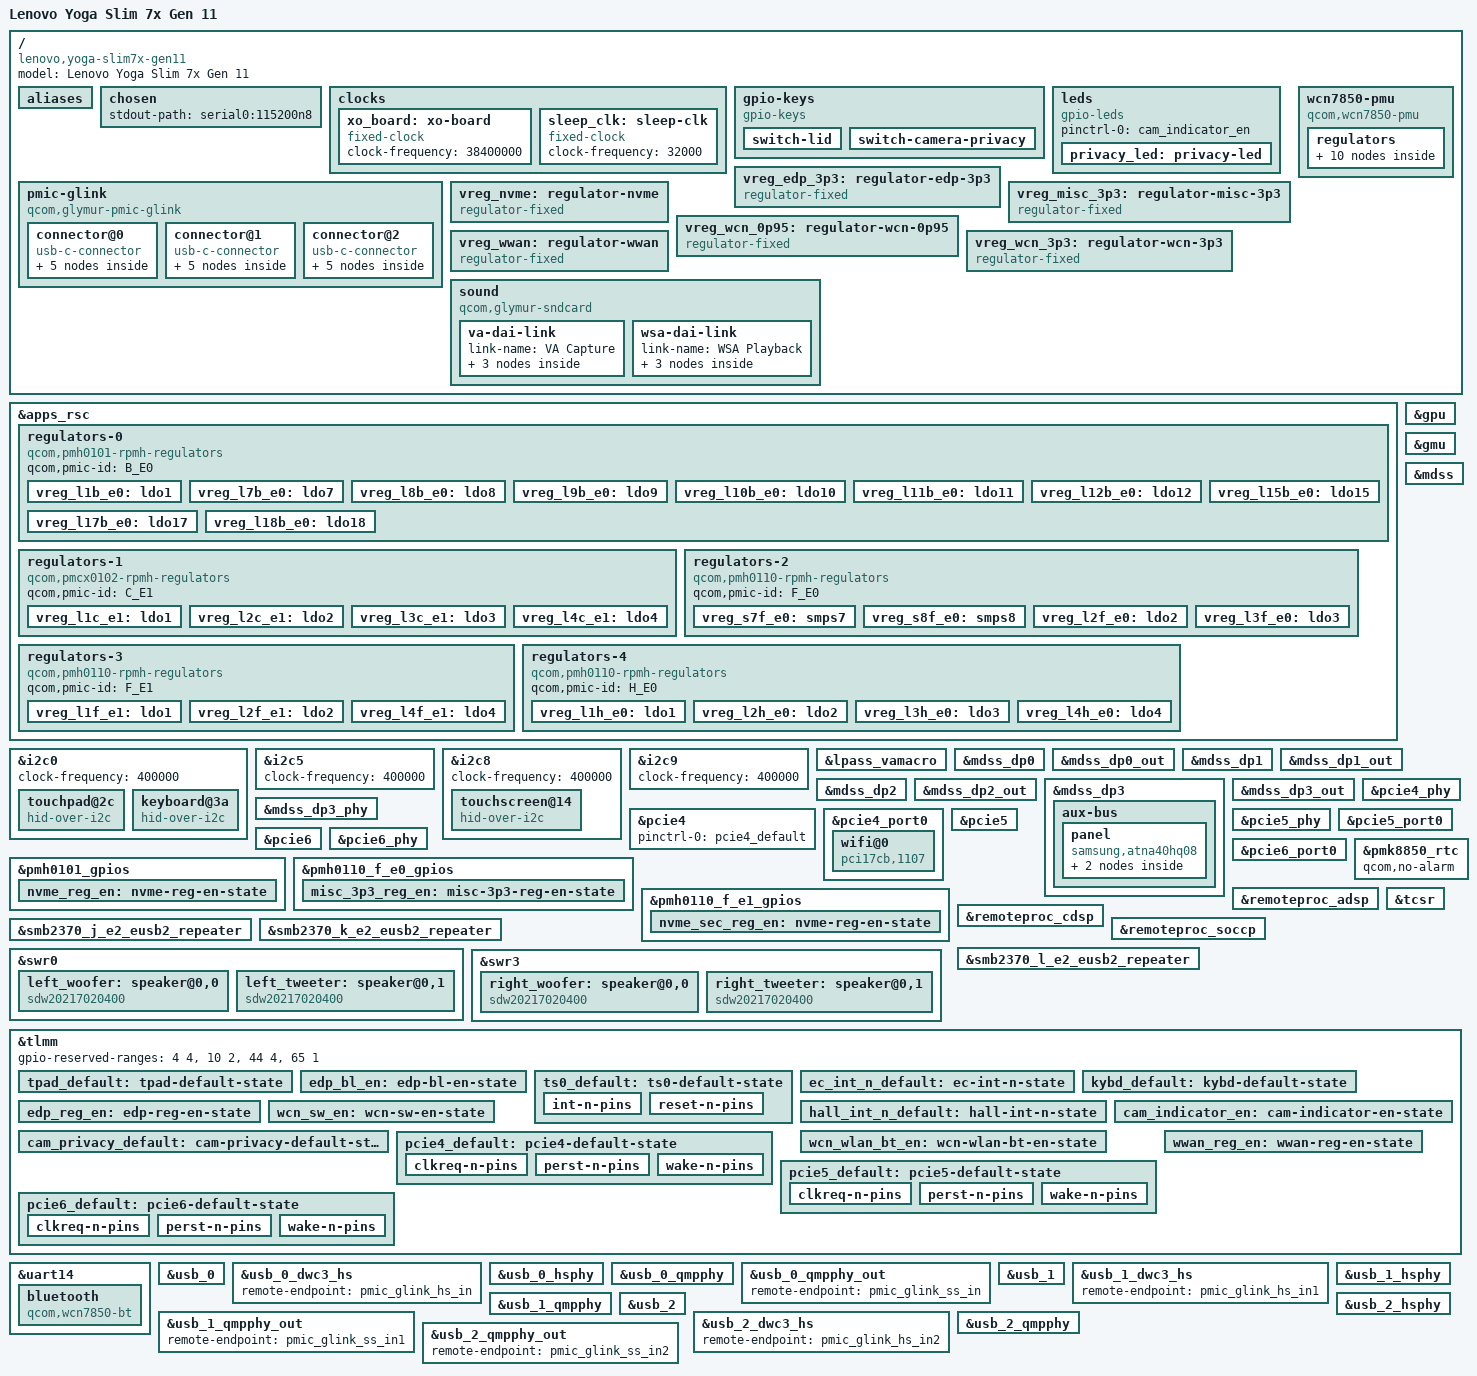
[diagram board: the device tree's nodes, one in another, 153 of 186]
// SPDX-License-Identifier: BSD-3-Clause
/*
 * Copyright (c) Qualcomm Technologies, Inc. and/or its subsidiaries.
 */
/dts-v1/;

#include "glymur.dtsi"

#include "pmcx0102.dtsi"        /* SPMI0: SID-2/3 SPMI1: SID-2/3 */
#include "pmh0101.dtsi"         /* SPMI0: SID-1                  */
#include "pmh0110-glymur.dtsi"  /* SPMI0: SID-5/7 SPMI1: SID-5   */
#include "pmh0104-glymur.dtsi"  /* SPMI0: SID-8/9 SPMI1: SID-11  */
#include "pmk8850.dtsi"         /* SPMI0: SID-0                  */
#include "smb2370.dtsi"         /* SPMI2: SID-9/10/11            */

#include <dt-bindings/input/gpio-keys.h>
#include <dt-bindings/leds/common.h>
#include <dt-bindings/pinctrl/qcom,pmic-gpio.h>

/ {
	model = "Lenovo Yoga Slim 7x Gen 11";
	compatible = "lenovo,yoga-slim7x-gen11", "qcom,glymur";

	aliases {
		serial0 = &uart21;
		serial1 = &uart14;
		i2c0 = &i2c0;
		i2c5 = &i2c5;
		i2c8 = &i2c8;
		i2c9 = &i2c9;
	};

	chosen {
		stdout-path = "serial0:115200n8";
	};

	clocks {
		xo_board: xo-board {
			compatible = "fixed-clock";
			clock-frequency = <38400000>;
			#clock-cells = <0>;
		};

		sleep_clk: sleep-clk {
			compatible = "fixed-clock";
			clock-frequency = <32000>;
			#clock-cells = <0>;
		};
	};

	gpio-keys {
		compatible = "gpio-keys";

		pinctrl-0 = <&hall_int_n_default>, <&cam_privacy_default>;
		pinctrl-names = "default";

		switch-lid {
			label = "lid";
			gpios = <&tlmm 92 GPIO_ACTIVE_LOW>;
			linux,input-type = <EV_SW>;
			linux,code = <SW_LID>;
			wakeup-source;
			wakeup-event-action = <EV_ACT_DEASSERTED>;
		};

		switch-camera-privacy {
			label = "Camera privacy switch";
			gpios = <&tlmm 99 GPIO_ACTIVE_LOW>;
			linux,input-type = <EV_SW>;
			linux,code = <SW_CAMERA_LENS_COVER>;
		};
	};

	leds {
		compatible = "gpio-leds";

		pinctrl-0 = <&cam_indicator_en>;
		pinctrl-names = "default";

		privacy_led: privacy-led {
			function = LED_FUNCTION_INDICATOR;
			color = <LED_COLOR_ID_WHITE>;
			gpios = <&tlmm 111 GPIO_ACTIVE_HIGH>;
			default-state = "off";
			panic-indicator;
		};
	};

	pmic-glink {
		compatible = "qcom,glymur-pmic-glink",
			     "qcom,pmic-glink";
		#address-cells = <1>;
		#size-cells = <0>;

		/* Left side display-adjacent port */
		connector@0 {
			compatible = "usb-c-connector";
			reg = <0>;
			power-role = "dual";
			data-role = "dual";

			ports {
				#address-cells = <1>;
				#size-cells = <0>;

				port@0 {
					reg = <0>;

					pmic_glink_hs_in: endpoint {
						remote-endpoint = <&usb_0_dwc3_hs>;
					};
				};

				port@1 {
					reg = <1>;

					pmic_glink_ss_in: endpoint {
						remote-endpoint = <&usb_0_qmpphy_out>;
					};
				};
			};
		};

		/* Left side user-adjacent port */
		connector@1 {
			compatible = "usb-c-connector";
			reg = <1>;
			power-role = "dual";
			data-role = "dual";

			ports {
				#address-cells = <1>;
				#size-cells = <0>;

				port@0 {
					reg = <0>;

					pmic_glink_hs_in1: endpoint {
						remote-endpoint = <&usb_1_dwc3_hs>;
					};
				};

				port@1 {
					reg = <1>;

					pmic_glink_ss_in1: endpoint {
						remote-endpoint = <&usb_1_qmpphy_out>;
					};
				};
			};
		};

		/* Right side port */
		connector@2 {
			compatible = "usb-c-connector";
			reg = <2>;
			power-role = "dual";
			data-role = "dual";

			ports {
				#address-cells = <1>;
				#size-cells = <0>;

				port@0 {
					reg = <0>;

					pmic_glink_hs_in2: endpoint {
						remote-endpoint = <&usb_2_dwc3_hs>;
					};
				};

				port@1 {
					reg = <1>;

					pmic_glink_ss_in2: endpoint {
						remote-endpoint = <&usb_2_qmpphy_out>;
					};
				};
			};
		};
	};

	vreg_edp_3p3: regulator-edp-3p3 {
		compatible = "regulator-fixed";

		regulator-name = "VREG_EDP_3P3";
		regulator-min-microvolt = <3300000>;
		regulator-max-microvolt = <3300000>;

		gpio = <&tlmm 70 GPIO_ACTIVE_HIGH>;
		enable-active-high;

		pinctrl-0 = <&edp_reg_en>;
		pinctrl-names = "default";

		regulator-boot-on;
	};

	vreg_misc_3p3: regulator-misc-3p3 {
		compatible = "regulator-fixed";

		regulator-name = "VREG_MISC_3P3";
		regulator-min-microvolt = <3300000>;
		regulator-max-microvolt = <3300000>;

		gpio = <&pmh0110_f_e0_gpios 6 GPIO_ACTIVE_HIGH>;
		enable-active-high;

		pinctrl-0 = <&misc_3p3_reg_en>;
		pinctrl-names = "default";

		regulator-boot-on;
	};

	vreg_nvme: regulator-nvme {
		compatible = "regulator-fixed";

		regulator-name = "VREG_NVME_3P3";
		regulator-min-microvolt = <3300000>;
		regulator-max-microvolt = <3300000>;

		gpio = <&pmh0101_gpios 14 GPIO_ACTIVE_HIGH>;
		enable-active-high;

		pinctrl-0 = <&nvme_reg_en>;
		pinctrl-names = "default";

		regulator-boot-on;
	};

	vreg_wcn_0p95: regulator-wcn-0p95 {
		compatible = "regulator-fixed";

		regulator-name = "VREG_WCN_0P95";
		regulator-min-microvolt = <950000>;
		regulator-max-microvolt = <950000>;

		vin-supply = <&vreg_wcn_3p3>;
	};

	vreg_wcn_3p3: regulator-wcn-3p3 {
		compatible = "regulator-fixed";

		regulator-name = "VREG_WCN_3P3";
		regulator-min-microvolt = <3300000>;
		regulator-max-microvolt = <3300000>;

		gpio = <&tlmm 94 GPIO_ACTIVE_HIGH>;
		enable-active-high;

		pinctrl-0 = <&wcn_sw_en>;
		pinctrl-names = "default";

		regulator-boot-on;
	};

	vreg_wwan: regulator-wwan {
		compatible = "regulator-fixed";

		regulator-name = "VREG_WWAN_3P3";
		regulator-min-microvolt = <3300000>;
		regulator-max-microvolt = <3300000>;

		gpio = <&tlmm 246 GPIO_ACTIVE_HIGH>;
		enable-active-high;

		pinctrl-0 = <&wwan_reg_en>;
		pinctrl-names = "default";
	};

	sound {
		compatible = "qcom,glymur-sndcard";
		model = "GLYMUR-LENOVO-Yoga-Slim7x";
		audio-routing = "WooferLeft IN", "WSA WSA_SPK1 OUT",
				"TweeterLeft IN", "WSA WSA_SPK2 OUT",
				"WooferRight IN", "WSA2 WSA_SPK1 OUT",
				"TweeterRight IN", "WSA2 WSA_SPK2 OUT",
				"VA DMIC0", "vdd-micb",
				"VA DMIC1", "vdd-micb",
				"VA DMIC2", "vdd-micb",
				"VA DMIC3", "vdd-micb";

		va-dai-link {
			link-name = "VA Capture";

			codec {
				sound-dai = <&lpass_vamacro 0>;
			};

			cpu {
				sound-dai = <&q6apmbedai VA_CODEC_DMA_TX_0>;
			};

			platform {
				sound-dai = <&q6apm>;
			};
		};

		wsa-dai-link {
			link-name = "WSA Playback";

			codec {
				sound-dai = <&left_woofer>, <&left_tweeter>,
					    <&swr0 0>, <&lpass_wsamacro 0>,
					    <&right_woofer>, <&right_tweeter>,
					    <&swr3 0>, <&lpass_wsa2macro 0>;
			};

			cpu {
				sound-dai = <&q6apmbedai WSA_CODEC_DMA_RX_0>;
			};

			platform {
				sound-dai = <&q6apm>;
			};
		};
	};

	wcn7850-pmu {
		compatible = "qcom,wcn7850-pmu";

		vdd-supply = <&vreg_wcn_0p95>;
		vddio-supply = <&vreg_l15b_e0>;
		vddaon-supply = <&vreg_l15b_e0>;
		vdddig-supply = <&vreg_l15b_e0>;
		vddrfa1p2-supply = <&vreg_l15b_e0>;
		vddrfa1p8-supply = <&vreg_l15b_e0>;

		wlan-enable-gpios = <&tlmm 117 GPIO_ACTIVE_HIGH>;
		bt-enable-gpios = <&tlmm 116 GPIO_ACTIVE_HIGH>;

		pinctrl-0 = <&wcn_wlan_bt_en>;
		pinctrl-names = "default";

		regulators {
			vreg_pmu_rfa_cmn: ldo0 {
				regulator-name = "vreg_pmu_rfa_cmn";
			};

			vreg_pmu_aon_0p59: ldo1 {
				regulator-name = "vreg_pmu_aon_0p59";
			};

			vreg_pmu_wlcx_0p8: ldo2 {
				regulator-name = "vreg_pmu_wlcx_0p8";
			};

			vreg_pmu_wlmx_0p85: ldo3 {
				regulator-name = "vreg_pmu_wlmx_0p85";
			};

			vreg_pmu_btcmx_0p85: ldo4 {
				regulator-name = "vreg_pmu_btcmx_0p85";
			};

			vreg_pmu_rfa_0p8: ldo5 {
				regulator-name = "vreg_pmu_rfa_0p8";
			};

			vreg_pmu_rfa_1p2: ldo6 {
				regulator-name = "vreg_pmu_rfa_1p2";
			};

			vreg_pmu_rfa_1p8: ldo7 {
				regulator-name = "vreg_pmu_rfa_1p8";
			};

			vreg_pmu_pcie_0p9: ldo8 {
				regulator-name = "vreg_pmu_pcie_0p9";
			};

			vreg_pmu_pcie_1p8: ldo9 {
				regulator-name = "vreg_pmu_pcie_1p8";
			};
		};
	};
};

&apps_rsc {
	regulators-0 {
		compatible = "qcom,pmh0101-rpmh-regulators";
		qcom,pmic-id = "B_E0";

		vreg_l1b_e0: ldo1 {
			regulator-name = "vreg_l1b_e0";
			regulator-min-microvolt = <1800000>;
			regulator-max-microvolt = <1800000>;
			regulator-initial-mode = <RPMH_REGULATOR_MODE_HPM>;
		};

		vreg_l7b_e0: ldo7 {
			regulator-name = "vreg_l7b_e0";
			regulator-min-microvolt = <3072000>;
			regulator-max-microvolt = <3072000>;
			regulator-initial-mode = <RPMH_REGULATOR_MODE_HPM>;
		};

		vreg_l8b_e0: ldo8 {
			regulator-name = "vreg_l8b_e0";
			regulator-min-microvolt = <3304000>;
			regulator-max-microvolt = <3304000>;
			regulator-initial-mode = <RPMH_REGULATOR_MODE_HPM>;
		};

		vreg_l9b_e0: ldo9 {
			regulator-name = "vreg_l9b_e0";
			regulator-min-microvolt = <2960000>;
			regulator-max-microvolt = <2960000>;
			regulator-initial-mode = <RPMH_REGULATOR_MODE_HPM>;
		};

		vreg_l10b_e0: ldo10 {
			regulator-name = "vreg_l10b_e0";
			regulator-min-microvolt = <1800000>;
			regulator-max-microvolt = <1800000>;
			regulator-initial-mode = <RPMH_REGULATOR_MODE_HPM>;
		};

		vreg_l11b_e0: ldo11 {
			regulator-name = "vreg_l11b_e0";
			regulator-min-microvolt = <1200000>;
			regulator-max-microvolt = <1200000>;
			regulator-initial-mode = <RPMH_REGULATOR_MODE_HPM>;
		};

		vreg_l12b_e0: ldo12 {
			regulator-name = "vreg_l12b_e0";
			regulator-min-microvolt = <1200000>;
			regulator-max-microvolt = <1200000>;
			regulator-initial-mode = <RPMH_REGULATOR_MODE_HPM>;
		};

		vreg_l15b_e0: ldo15 {
			regulator-name = "vreg_l15b_e0";
			regulator-min-microvolt = <1800000>;
			regulator-max-microvolt = <1800000>;
			regulator-initial-mode = <RPMH_REGULATOR_MODE_HPM>;
		};

		vreg_l17b_e0: ldo17 {
			regulator-name = "vreg_l17b_e0";
			regulator-min-microvolt = <2504000>;
			regulator-max-microvolt = <2504000>;
			regulator-initial-mode = <RPMH_REGULATOR_MODE_HPM>;
		};

		vreg_l18b_e0: ldo18 {
			regulator-name = "vreg_l18b_e0";
			regulator-min-microvolt = <1200000>;
			regulator-max-microvolt = <1200000>;
			regulator-initial-mode = <RPMH_REGULATOR_MODE_HPM>;
		};
	};

	regulators-1 {
		compatible = "qcom,pmcx0102-rpmh-regulators";
		qcom,pmic-id = "C_E1";

		vreg_l1c_e1: ldo1 {
			regulator-name = "vreg_l1c_e1";
			regulator-min-microvolt = <912000>;
			regulator-max-microvolt = <912000>;
			regulator-initial-mode = <RPMH_REGULATOR_MODE_HPM>;
		};

		vreg_l2c_e1: ldo2 {
			regulator-name = "vreg_l2c_e1";
			regulator-min-microvolt = <1200000>;
			regulator-max-microvolt = <1200000>;
			regulator-initial-mode = <RPMH_REGULATOR_MODE_HPM>;
		};

		vreg_l3c_e1: ldo3 {
			regulator-name = "vreg_l3c_e1";
			regulator-min-microvolt = <936000>;
			regulator-max-microvolt = <936000>;
			regulator-initial-mode = <RPMH_REGULATOR_MODE_HPM>;
		};

		vreg_l4c_e1: ldo4 {
			regulator-name = "vreg_l4c_e1";
			regulator-min-microvolt = <912000>;
			regulator-max-microvolt = <912000>;
			regulator-initial-mode = <RPMH_REGULATOR_MODE_HPM>;
		};
	};

	regulators-2 {
		compatible = "qcom,pmh0110-rpmh-regulators";
		qcom,pmic-id = "F_E0";

		vreg_s7f_e0: smps7 {
			regulator-name = "vreg_s7f_e0";
			regulator-min-microvolt = <1200000>;
			regulator-max-microvolt = <1200000>;
			regulator-initial-mode = <RPMH_REGULATOR_MODE_HPM>;
		};

		vreg_s8f_e0: smps8 {
			regulator-name = "vreg_s8f_e0";
			regulator-min-microvolt = <952000>;
			regulator-max-microvolt = <952000>;
			regulator-initial-mode = <RPMH_REGULATOR_MODE_HPM>;
		};

		vreg_l2f_e0: ldo2 {
			regulator-name = "vreg_l2f_e0";
			regulator-min-microvolt = <936000>;
			regulator-max-microvolt = <936000>;
			regulator-initial-mode = <RPMH_REGULATOR_MODE_HPM>;
		};

		vreg_l3f_e0: ldo3 {
			regulator-name = "vreg_l3f_e0";
			regulator-min-microvolt = <912000>;
			regulator-max-microvolt = <912000>;
			regulator-initial-mode = <RPMH_REGULATOR_MODE_HPM>;
		};
	};

	regulators-3 {
		compatible = "qcom,pmh0110-rpmh-regulators";
		qcom,pmic-id = "F_E1";

		vreg_l1f_e1: ldo1 {
			regulator-name = "vreg_l1f_e1";
			regulator-min-microvolt = <880000>;
			regulator-max-microvolt = <904000>;
			regulator-initial-mode = <RPMH_REGULATOR_MODE_HPM>;
		};

		vreg_l2f_e1: ldo2 {
			regulator-name = "vreg_l2f_e1";
			regulator-min-microvolt = <880000>;
			regulator-max-microvolt = <880000>;
			regulator-initial-mode = <RPMH_REGULATOR_MODE_HPM>;
		};

		vreg_l4f_e1: ldo4 {
			regulator-name = "vreg_l4f_e1";
			regulator-min-microvolt = <1200000>;
			regulator-max-microvolt = <1200000>;
			regulator-initial-mode = <RPMH_REGULATOR_MODE_HPM>;
		};
	};

	regulators-4 {
		compatible = "qcom,pmh0110-rpmh-regulators";
		qcom,pmic-id = "H_E0";

		vreg_l1h_e0: ldo1 {
			regulator-name = "vreg_l1h_e0";
			regulator-min-microvolt = <936000>;
			regulator-max-microvolt = <936000>;
			regulator-initial-mode = <RPMH_REGULATOR_MODE_HPM>;
		};

		vreg_l2h_e0: ldo2 {
			regulator-name = "vreg_l2h_e0";
			regulator-min-microvolt = <880000>;
			regulator-max-microvolt = <880000>;
			regulator-initial-mode = <RPMH_REGULATOR_MODE_HPM>;
		};

		vreg_l3h_e0: ldo3 {
			regulator-name = "vreg_l3h_e0";
			regulator-min-microvolt = <1800000>;
			regulator-max-microvolt = <1800000>;
			regulator-initial-mode = <RPMH_REGULATOR_MODE_HPM>;
		};

		vreg_l4h_e0: ldo4 {
			regulator-name = "vreg_l4h_e0";
			regulator-min-microvolt = <1200000>;
			regulator-max-microvolt = <1200000>;
			regulator-initial-mode = <RPMH_REGULATOR_MODE_HPM>;
		};
	};
};

&gpu {
	status = "okay";
};

&gmu {
	status = "okay";
};

&i2c0 {
	clock-frequency = <400000>;

	status = "okay";

	touchpad@2c {
		compatible = "hid-over-i2c";
		reg = <0x2c>;

		hid-descr-addr = <0x20>;
		interrupts-extended = <&tlmm 3 IRQ_TYPE_LEVEL_LOW>;

		vdd-supply = <&vreg_misc_3p3>;
		vddl-supply = <&vreg_l15b_e0>;

		pinctrl-0 = <&tpad_default>;
		pinctrl-names = "default";

		wakeup-source;
	};

	keyboard@3a {
		compatible = "hid-over-i2c";
		reg = <0x3a>;

		hid-descr-addr = <0x1>;
		interrupts-extended = <&tlmm 67 IRQ_TYPE_LEVEL_LOW>;

		vdd-supply = <&vreg_misc_3p3>;
		vddl-supply = <&vreg_l15b_e0>;

		pinctrl-0 = <&kybd_default>;
		pinctrl-names = "default";

		wakeup-source;
	};

	/* Something @ 0x5b */
};

&i2c5 {
	clock-frequency = <400000>;

	status = "okay";
};

&i2c8 {
	clock-frequency = <400000>;

	status = "okay";

	touchscreen@14 {
		compatible = "hid-over-i2c";
		reg = <0x14>;

		hid-descr-addr = <0x1>;
		interrupts-extended = <&tlmm 51 IRQ_TYPE_LEVEL_LOW>;

		post-power-on-delay-ms = <200>;

		vdd-supply = <&vreg_misc_3p3>;
		vddl-supply = <&vreg_l15b_e0>;

		pinctrl-0 = <&ts0_default>;
		pinctrl-names = "default";
	};
};

&i2c9 {
	clock-frequency = <400000>;

	status = "okay";

	/* EC @ 0x70, irq = TLMM 66 */
};

&lpass_vamacro {
	pinctrl-0 = <&dmic01_default>, <&dmic23_default>;
	pinctrl-names = "default";
	qcom,dmic-sample-rate = <4800000>;
};

&mdss {
	status = "okay";
};

&mdss_dp0 {
	status = "okay";
};

&mdss_dp0_out {
	link-frequencies = /bits/ 64 <1620000000 2700000000 5400000000 8100000000>;
};

&mdss_dp1 {
	status = "okay";
};

&mdss_dp1_out {
	link-frequencies = /bits/ 64 <1620000000 2700000000 5400000000 8100000000>;
};

&mdss_dp2 {
	status = "okay";
};

&mdss_dp2_out {
	link-frequencies = /bits/ 64 <1620000000 2700000000 5400000000 8100000000>;
};

&mdss_dp3 {
	/delete-property/ #sound-dai-cells;

	status = "okay";

	aux-bus {
		panel {
			compatible = "samsung,atna40hq08", "samsung,atna33xc20";
			enable-gpios = <&tlmm 18 GPIO_ACTIVE_HIGH>;
			power-supply = <&vreg_edp_3p3>;

			pinctrl-0 = <&edp_bl_en>;
			pinctrl-names = "default";

			port {
				edp_panel_in: endpoint {
					remote-endpoint = <&mdss_dp3_out>;
				};
			};
		};
	};
};

&mdss_dp3_out {
	data-lanes = <0 1 2 3>;
	link-frequencies = /bits/ 64 <1620000000 2700000000 5400000000 8100000000>;

	remote-endpoint = <&edp_panel_in>;
};

&mdss_dp3_phy {
	vdda-phy-supply = <&vreg_l2f_e1>;
	vdda-pll-supply = <&vreg_l4f_e1>;

	status = "okay";
};

&pcie4 {
	pinctrl-0 = <&pcie4_default>;
	pinctrl-names = "default";

	status = "okay";
};

&pcie4_phy {
	vdda-phy-supply = <&vreg_l1c_e1>;
	vdda-pll-supply = <&vreg_l4f_e1>;

	status = "okay";
};

&pcie4_port0 {
	reset-gpios = <&tlmm 146 GPIO_ACTIVE_LOW>;
	wake-gpios = <&tlmm 148 GPIO_ACTIVE_LOW>;

	wifi@0 {
		compatible = "pci17cb,1107";
		reg = <0x10000 0x0 0x0 0x0 0x0>;

		vddaon-supply = <&vreg_pmu_aon_0p59>;
		vddwlcx-supply = <&vreg_pmu_wlcx_0p8>;
		vddwlmx-supply = <&vreg_pmu_wlmx_0p85>;
		vddrfacmn-supply = <&vreg_pmu_rfa_cmn>;
		vddrfa0p8-supply = <&vreg_pmu_rfa_0p8>;
		vddrfa1p2-supply = <&vreg_pmu_rfa_1p2>;
		vddrfa1p8-supply = <&vreg_pmu_rfa_1p8>;
		vddpcie0p9-supply = <&vreg_pmu_pcie_0p9>;
		vddpcie1p8-supply = <&vreg_pmu_pcie_1p8>;
	};
};

&pcie5 {
	vddpe-3v3-supply = <&vreg_nvme>;

	pinctrl-0 = <&pcie5_default>;
	pinctrl-names = "default";

	status = "okay";
};

&pcie5_phy {
	vdda-phy-supply = <&vreg_l2f_e0>;
	vdda-pll-supply = <&vreg_l4h_e0>;

	status = "okay";
};

&pcie5_port0 {
	reset-gpios = <&tlmm 152 GPIO_ACTIVE_LOW>;
	wake-gpios = <&tlmm 154 GPIO_ACTIVE_LOW>;
};

&pcie6 {
	vddpe-3v3-supply = <&vreg_wwan>;

	pinctrl-0 = <&pcie6_default>;
	pinctrl-names = "default";

	status = "okay";
};

&pcie6_phy {
	vdda-phy-supply = <&vreg_l1c_e1>;
	vdda-pll-supply = <&vreg_l4f_e1>;

	status = "okay";
};

&pcie6_port0 {
	reset-gpios = <&tlmm 149 GPIO_ACTIVE_LOW>;
	wake-gpios = <&tlmm 151 GPIO_ACTIVE_LOW>;
};

&pmh0101_gpios {
	nvme_reg_en: nvme-reg-en-state {
		pins = "gpio14";
		function = "normal";
		bias-disable;
	};
};

&pmh0110_f_e0_gpios {
	misc_3p3_reg_en: misc-3p3-reg-en-state {
		pins = "gpio6";
		function = "normal";
		bias-disable;
		input-disable;
		output-enable;
		drive-push-pull;
		power-source = <1>; /* 1.8 V */
		qcom,drive-strength = <PMIC_GPIO_STRENGTH_LOW>;
	};
};

&pmh0110_f_e1_gpios {
	nvme_sec_reg_en: nvme-reg-en-state {
		pins = "gpio14";
		function = "normal";
		bias-disable;
	};
};

&pmk8850_rtc {
	qcom,no-alarm;
};

&remoteproc_adsp {
	firmware-name = "qcom/glymur/LENOVO/83QR/qcadsp8480.mbn",
			"qcom/glymur/LENOVO/83QR/adsp_dtbs.elf";

	status = "okay";
};

&remoteproc_cdsp {
	firmware-name = "qcom/glymur/LENOVO/83QR/qccdsp8480.mbn",
			"qcom/glymur/LENOVO/83QR/cdsp_dtbs.elf";

	status = "okay";
};

&remoteproc_soccp {
	status = "okay";
};

&smb2370_j_e2_eusb2_repeater {
	vdd18-supply = <&vreg_l15b_e0>;
	vdd3-supply = <&vreg_l7b_e0>;
};

&smb2370_k_e2_eusb2_repeater {
	vdd18-supply = <&vreg_l15b_e0>;
	vdd3-supply = <&vreg_l7b_e0>;
};

&smb2370_l_e2_eusb2_repeater {
	vdd18-supply = <&vreg_l15b_e0>;
	vdd3-supply = <&vreg_l7b_e0>;

	status = "okay";
};

&swr0 {
	status = "okay";

	/* WSA8845, Left Woofer */
	left_woofer: speaker@0,0 {
		compatible = "sdw20217020400";
		reg = <0 0>;
		reset-gpios = <&lpass_tlmm 12 GPIO_ACTIVE_LOW>;
		#sound-dai-cells = <0>;
		sound-name-prefix = "WooferLeft";
		vdd-1p8-supply = <&vreg_l15b_e0>;
		vdd-io-supply = <&vreg_l18b_e0>;
		qcom,port-mapping = <1 2 3 7 12 14>;
	};

	/* WSA8845, Left Tweeter */
	left_tweeter: speaker@0,1 {
		compatible = "sdw20217020400";
		reg = <0 1>;
		reset-gpios = <&lpass_tlmm 12 GPIO_ACTIVE_LOW>;
		#sound-dai-cells = <0>;
		sound-name-prefix = "TweeterLeft";
		vdd-1p8-supply = <&vreg_l15b_e0>;
		vdd-io-supply = <&vreg_l18b_e0>;
		qcom,port-mapping = <4 5 6 7 13 15>;
	};
};

&swr3 {
	status = "okay";

	/* WSA8845, Right Woofer */
	right_woofer: speaker@0,0 {
		compatible = "sdw20217020400";
		reg = <0 0>;
		reset-gpios = <&lpass_tlmm 13 GPIO_ACTIVE_LOW>;
		#sound-dai-cells = <0>;
		sound-name-prefix = "WooferRight";
		vdd-1p8-supply = <&vreg_l15b_e0>;
		vdd-io-supply = <&vreg_l18b_e0>;
		qcom,port-mapping = <1 2 3 7 12 14>;
	};

	/* WSA8845, Right Tweeter */
	right_tweeter: speaker@0,1 {
		compatible = "sdw20217020400";
		reg = <0 1>;
		reset-gpios = <&lpass_tlmm 13 GPIO_ACTIVE_LOW>;
		#sound-dai-cells = <0>;
		sound-name-prefix = "TweeterRight";
		vdd-1p8-supply = <&vreg_l15b_e0>;
		vdd-io-supply = <&vreg_l18b_e0>;
		qcom,port-mapping = <4 5 6 7 13 15>;
	};
};

&tcsr {
	vdda-qrefrpt0-0p9-supply = <&vreg_l2f_e1>;
	vdda-qrefrpt1-0p9-supply = <&vreg_l2f_e1>;
	vdda-qrefrpt2-0p9-supply = <&vreg_l2f_e1>;
	vdda-qrefrpt3-0p9-supply = <&vreg_l2h_e0>;
	vdda-qrefrpt4-0p9-supply = <&vreg_l2h_e0>;
	vdda-qrefrx0-0p9-supply = <&vreg_l2f_e1>;
	vdda-qrefrx1-0p9-supply = <&vreg_l2f_e1>;
	vdda-qrefrx2-0p9-supply = <&vreg_l2f_e1>;
	vdda-qrefrx4-0p9-supply = <&vreg_l2h_e0>;
	vdda-qrefrx5-0p9-supply = <&vreg_l3f_e0>;
	vdda-qreftx0-0p9-supply = <&vreg_l3f_e0>;
	vdda-qreftx0-1p2-supply = <&vreg_l4h_e0>;
	vdda-qreftx1-0p9-supply = <&vreg_l1f_e1>;
	vdda-refgen3-0p9-supply = <&vreg_l2f_e0>;
	vdda-refgen3-1p2-supply = <&vreg_l4h_e0>;
	vdda-refgen4-0p9-supply = <&vreg_l1f_e1>;
	vdda-refgen4-1p2-supply = <&vreg_l4f_e1>;
};

&tlmm {
	gpio-reserved-ranges = <4 4>, /* EC TZ Secure I3C */
			       <10 2>, /* OOB UART */
			       <44 4>, /* Security SPI (TPM) */
			       <65 1>; /* EC reset (need to unplug the battery if asserted) */

	tpad_default: tpad-default-state {
		pins = "gpio3";
		function = "gpio";
		bias-disable;
	};

	edp_bl_en: edp-bl-en-state {
		pins = "gpio18";
		function = "gpio";
		drive-strength = <16>;
		bias-disable;
	};

	ts0_default: ts0-default-state {
		int-n-pins {
			pins = "gpio51";
			function = "gpio";
			bias-disable;
		};

		reset-n-pins {
			pins = "gpio48";
			function = "gpio";
			drive-strength = <16>;
			bias-disable;
		};
	};

	ec_int_n_default: ec-int-n-state {
		pins = "gpio66";
		function = "gpio";
		bias-disable;
	};

	kybd_default: kybd-default-state {
		pins = "gpio67";
		function = "gpio";
		bias-disable;
	};

	edp_reg_en: edp-reg-en-state {
		pins = "gpio70";
		function = "gpio";
		drive-strength = <16>;
		bias-disable;
	};

	hall_int_n_default: hall-int-n-state {
		pins = "gpio92";
		function = "gpio";
		bias-disable;
	};

	wcn_sw_en: wcn-sw-en-state {
		pins = "gpio94";
		function = "gpio";
		drive-strength = <2>;
		bias-disable;
	};

	cam_privacy_default: cam-privacy-default-state {
		pins = "gpio99";
		function = "gpio";
		bias-pull-up;
	};

	cam_indicator_en: cam-indicator-en-state {
		pins = "gpio111";
		function = "gpio";
		drive-strength = <2>;
		bias-disable;
	};

	wcn_wlan_bt_en: wcn-wlan-bt-en-state {
		pins = "gpio116", "gpio117";
		function = "gpio";
		drive-strength = <2>;
		bias-disable;
	};

	pcie4_default: pcie4-default-state {
		clkreq-n-pins {
			pins = "gpio147";
			function = "pcie4_clk_req_n";
			drive-strength = <2>;
			bias-pull-up;
		};

		perst-n-pins {
			pins = "gpio146";
			function = "gpio";
			drive-strength = <2>;
			bias-disable;
		};

		wake-n-pins {
			pins = "gpio148";
			function = "gpio";
			drive-strength = <2>;
			bias-pull-up;
		};
	};

	pcie5_default: pcie5-default-state {
		clkreq-n-pins {
			pins = "gpio153";
			function = "pcie5_clk_req_n";
			drive-strength = <2>;
			bias-pull-up;
		};

		perst-n-pins {
			pins = "gpio152";
			function = "gpio";
			drive-strength = <2>;
			bias-disable;
		};

		wake-n-pins {
			pins = "gpio154";
			function = "gpio";
			drive-strength = <2>;
			bias-pull-up;
		};
	};

	pcie6_default: pcie6-default-state {
		clkreq-n-pins {
			pins = "gpio150";
			function = "pcie6_clk_req_n";
			drive-strength = <2>;
			bias-pull-up;
		};

		perst-n-pins {
			pins = "gpio149";
			function = "gpio";
			drive-strength = <2>;
			bias-disable;
		};

		wake-n-pins {
			pins = "gpio151";
			function = "gpio";
			drive-strength = <2>;
			bias-pull-up;
		};
	};

	wwan_reg_en: wwan-reg-en-state {
		pins = "gpio246";
		function = "gpio";
		drive-strength = <2>;
		bias-disable;
	};
};

&uart14 {
	status = "okay";

	bluetooth {
		compatible = "qcom,wcn7850-bt";
		max-speed = <3200000>;

		vddaon-supply = <&vreg_pmu_aon_0p59>;
		vddwlcx-supply = <&vreg_pmu_wlcx_0p8>;
		vddwlmx-supply = <&vreg_pmu_wlmx_0p85>;
		vddrfacmn-supply = <&vreg_pmu_rfa_cmn>;
		vddrfa0p8-supply = <&vreg_pmu_rfa_0p8>;
		vddrfa1p2-supply = <&vreg_pmu_rfa_1p2>;
		vddrfa1p8-supply = <&vreg_pmu_rfa_1p8>;
	};
};

&usb_0 {
	status = "okay";
};

&usb_0_dwc3_hs {
	remote-endpoint = <&pmic_glink_hs_in>;
};

&usb_0_hsphy {
	vdd-supply = <&vreg_l3f_e0>;
	vdda12-supply = <&vreg_l4h_e0>;

	phys = <&smb2370_j_e2_eusb2_repeater>;

	status = "okay";
};

&usb_0_qmpphy {
	vdda-phy-supply = <&vreg_l4h_e0>;
	vdda-pll-supply = <&vreg_l3f_e0>;
	refgen-supply = <&vreg_l2f_e0>;

	status = "okay";
};

&usb_0_qmpphy_out {
	remote-endpoint = <&pmic_glink_ss_in>;
};

&usb_1 {
	status = "okay";
};

&usb_1_dwc3_hs {
	remote-endpoint = <&pmic_glink_hs_in1>;
};

&usb_1_hsphy {
	vdd-supply = <&vreg_l3f_e0>;
	vdda12-supply = <&vreg_l4h_e0>;

	phys = <&smb2370_k_e2_eusb2_repeater>;

	status = "okay";
};

&usb_1_qmpphy {
	vdda-phy-supply = <&vreg_l4h_e0>;
	vdda-pll-supply = <&vreg_l1h_e0>;
	refgen-supply = <&vreg_l2f_e0>;

	status = "okay";
};

&usb_1_qmpphy_out {
	remote-endpoint = <&pmic_glink_ss_in1>;
};

&usb_2 {
	status = "okay";
};

&usb_2_dwc3_hs {
	remote-endpoint = <&pmic_glink_hs_in2>;
};

&usb_2_hsphy {
	vdd-supply = <&vreg_l4c_e1>;
	vdda12-supply = <&vreg_l4f_e1>;

	phys = <&smb2370_l_e2_eusb2_repeater>;

	status = "okay";
};

&usb_2_qmpphy {
	vdda-phy-supply = <&vreg_l4f_e1>;
	vdda-pll-supply = <&vreg_l4c_e1>;
	refgen-supply = <&vreg_l1c_e1>;

	status = "okay";
};

&usb_2_qmpphy_out {
	remote-endpoint = <&pmic_glink_ss_in2>;
};
